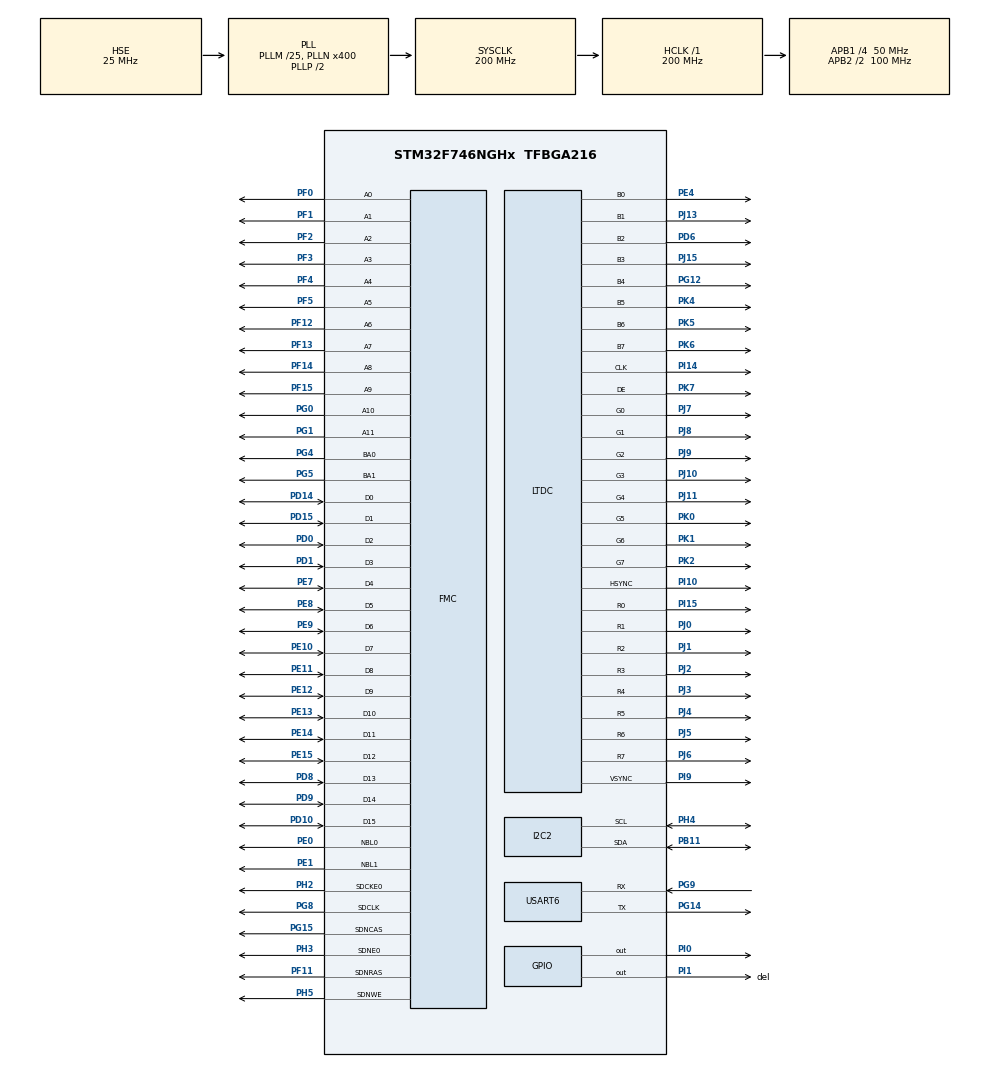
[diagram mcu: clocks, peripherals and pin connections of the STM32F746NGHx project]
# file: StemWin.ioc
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CORTEX_M7.AccessPermission-Cortex_Memory_Protection_Unit_Region0_Settings=MPU_REGION_FULL_ACCESS
CORTEX_M7.AccessPermission-Cortex_Memory_Protection_Unit_Region1_Settings=MPU_REGION_FULL_ACCESS
CORTEX_M7.AccessPermission-Cortex_Memory_Protection_Unit_Region2_Settings=MPU_REGION_FULL_ACCESS
CORTEX_M7.AccessPermission-Cortex_Memory_Protection_Unit_Region3_Settings=MPU_REGION_FULL_ACCESS
CORTEX_M7.BaseAddress-Cortex_Memory_Protection_Unit_Region0_Settings=0xC0000000
CORTEX_M7.BaseAddress-Cortex_Memory_Protection_Unit_Region1_Settings=0x2004C000
CORTEX_M7.BaseAddress-Cortex_Memory_Protection_Unit_Region2_Settings=0x2004C000
CORTEX_M7.BaseAddress-Cortex_Memory_Protection_Unit_Region3_Settings=0x20010000
CORTEX_M7.CPU_DCache=Enabled
CORTEX_M7.CPU_ICache=Enabled
CORTEX_M7.Enable-Cortex_Memory_Protection_Unit_Region0_Settings=MPU_REGION_ENABLE
CORTEX_M7.Enable-Cortex_Memory_Protection_Unit_Region1_Settings=MPU_REGION_ENABLE
CORTEX_M7.Enable-Cortex_Memory_Protection_Unit_Region2_Settings=MPU_REGION_ENABLE
CORTEX_M7.Enable-Cortex_Memory_Protection_Unit_Region3_Settings=MPU_REGION_ENABLE
CORTEX_M7.IsCacheable-Cortex_Memory_Protection_Unit_Region0_Settings=MPU_ACCESS_CACHEABLE
CORTEX_M7.MPU_Control=__NULL
CORTEX_M7.Size-Cortex_Memory_Protection_Unit_Region0_Settings=MPU_REGION_SIZE_8MB
CORTEX_M7.Size-Cortex_Memory_Protection_Unit_Region1_Settings=MPU_REGION_SIZE_16KB
CORTEX_M7.Size-Cortex_Memory_Protection_Unit_Region2_Settings=MPU_REGION_SIZE_512B
CORTEX_M7.Size-Cortex_Memory_Protection_Unit_Region3_Settings=MPU_REGION_SIZE_256KB
Dma.MEMTOMEM.0.Direction=DMA_MEMORY_TO_MEMORY
Dma.MEMTOMEM.0.FIFOMode=DMA_FIFOMODE_ENABLE
Dma.MEMTOMEM.0.FIFOThreshold=DMA_FIFO_THRESHOLD_FULL
Dma.MEMTOMEM.0.Instance=DMA2_Stream0
Dma.MEMTOMEM.0.MemBurst=DMA_MBURST_SINGLE
Dma.MEMTOMEM.0.MemDataAlignment=DMA_MDATAALIGN_BYTE
Dma.MEMTOMEM.0.MemInc=DMA_MINC_ENABLE
Dma.MEMTOMEM.0.Mode=DMA_NORMAL
Dma.MEMTOMEM.0.PeriphBurst=DMA_PBURST_SINGLE
Dma.MEMTOMEM.0.PeriphDataAlignment=DMA_PDATAALIGN_BYTE
Dma.MEMTOMEM.0.PeriphInc=DMA_PINC_ENABLE
Dma.MEMTOMEM.0.Priority=DMA_PRIORITY_LOW
Dma.Request0=MEMTOMEM
I2C2.Timing=0x00C0EAFF
LTDC.ActiveH=272
LTDC.ActiveW=480
LTDC.Alpha_L0=255
LTDC.BlendingFactor1_L0=LTDC_BLENDING_FACTOR1_PAxCA
LTDC.BlendingFactor2_L0=LTDC_BLENDING_FACTOR2_PAxCA
LTDC.FBStartAdress_L0=0xC0000000
LTDC.HBP=13
LTDC.HFP=32
LTDC.HSync=41
LTDC.ImageHeight_L0=272
LTDC.ImageWidth_L0=480
LTDC.Layers=0
LTDC.PixelFormat_L0=LTDC_PIXEL_FORMAT_RGB565
LTDC.VSync=10
LTDC.WindowX1_L0=480
LTDC.WindowY1_L0=272
Mcu.Family=STM32F7
Mcu.Name=STM32F746NGHx
Mcu.Package=TFBGA216
NVIC.DMA2D_IRQn=true\:5\:0\:true\:false\:true\:true\:true
NVIC.LTDC_IRQn=true\:5\:0\:true\:false\:true\:true\:true
NVIC.PriorityGroup=NVIC_PRIORITYGROUP_4
PA13.Mode=Trace_Asynchronous_SW
PA13.Signal=SYS_JTMS-SWDIO
PA14.Mode=Trace_Asynchronous_SW
PA14.Signal=SYS_JTCK-SWCLK
PB11.Mode=I2C
PB11.Signal=I2C2_SDA
PB3.Mode=Trace_Asynchronous_SW
PB3.Signal=SYS_JTDO-SWO
PC14/OSC32_IN.Mode=LSE-External-Oscillator
PC14/OSC32_IN.Signal=RCC_OSC32_IN
PC15/OSC32_OUT.Mode=LSE-External-Oscillator
PC15/OSC32_OUT.Signal=RCC_OSC32_OUT
PD0.Signal=FMC_D2_DA2
PD1.Signal=FMC_D3_DA3
PD10.Signal=FMC_D15_DA15
PD14.Signal=FMC_D0_DA0
PD15.Signal=FMC_D1_DA1
PD6.Mode=RGB888
PD6.Signal=LTDC_B2
PD8.Signal=FMC_D13_DA13
PD9.Signal=FMC_D14_DA14
PE0.Signal=FMC_NBL0
PE1.Signal=FMC_NBL1
PE10.Signal=FMC_D7_DA7
PE11.Signal=FMC_D8_DA8
PE12.Signal=FMC_D9_DA9
PE13.Signal=FMC_D10_DA10
PE14.Signal=FMC_D11_DA11
PE15.Signal=FMC_D12_DA12
PE4.Mode=RGB888
PE4.Signal=LTDC_B0
PE7.Signal=FMC_D4_DA4
PE8.Signal=FMC_D5_DA5
PE9.Signal=FMC_D6_DA6
PF0.Signal=FMC_A0
PF1.Signal=FMC_A1
PF11.Signal=FMC_SDNRAS
PF12.Signal=FMC_A6
PF13.Signal=FMC_A7
PF14.Signal=FMC_A8
PF15.Signal=FMC_A9
PF2.Signal=FMC_A2
PF3.Signal=FMC_A3
PF4.Signal=FMC_A4
PF5.Signal=FMC_A5
PG0.Signal=FMC_A10
PG1.Signal=FMC_A11
PG12.Mode=RGB888
PG12.Signal=LTDC_B4
PG14.Mode=Asynchronous
PG14.Signal=USART6_TX
PG15.Signal=FMC_SDNCAS
PG4.Signal=FMC_A14_BA0
PG5.Signal=FMC_A15_BA1
PG8.Signal=FMC_SDCLK
PG9.Mode=Asynchronous
PG9.Signal=USART6_RX
PH0/OSC_IN.Mode=HSE-External-Oscillator
PH0/OSC_IN.Signal=RCC_OSC_IN
PH1/OSC_OUT.Mode=HSE-External-Oscillator
PH1/OSC_OUT.Signal=RCC_OSC_OUT
PH2.Mode=SdramChipSelect1_1
PH2.Signal=FMC_SDCKE0
PH3.Mode=SdramChipSelect1_1
PH3.Signal=FMC_SDNE0
PH4.Mode=I2C
PH4.Signal=I2C2_SCL
PH5.Signal=FMC_SDNWE
PI0.Signal=GPIO_Output
PI1.GPIO_Label=del
PI1.Signal=GPIO_Output
PI10.Mode=RGB888
PI10.Signal=LTDC_HSYNC
PI14.Mode=RGB888
PI14.Signal=LTDC_CLK
PI15.Mode=RGB888
PI15.Signal=LTDC_R0
PI9.Mode=RGB888
PI9.Signal=LTDC_VSYNC
PJ0.Mode=RGB888
PJ0.Signal=LTDC_R1
PJ1.Mode=RGB888
PJ1.Signal=LTDC_R2
PJ10.Mode=RGB888
PJ10.Signal=LTDC_G3
PJ11.Mode=RGB888
PJ11.Signal=LTDC_G4
PJ13.Mode=RGB888
PJ13.Signal=LTDC_B1
PJ15.Mode=RGB888
PJ15.Signal=LTDC_B3
PJ2.Mode=RGB888
PJ2.Signal=LTDC_R3
PJ3.Mode=RGB888
PJ3.Signal=LTDC_R4
PJ4.Mode=RGB888
PJ4.Signal=LTDC_R5
PJ5.Mode=RGB888
PJ5.Signal=LTDC_R6
PJ6.Mode=RGB888
PJ6.Signal=LTDC_R7
PJ7.Mode=RGB888
PJ7.Signal=LTDC_G0
PJ8.Mode=RGB888
PJ8.Signal=LTDC_G1
PJ9.Mode=RGB888
PJ9.Signal=LTDC_G2
PK0.Mode=RGB888
PK0.Signal=LTDC_G5
PK1.Mode=RGB888
PK1.Signal=LTDC_G6
PK2.Mode=RGB888
PK2.Signal=LTDC_G7
PK4.Mode=RGB888
PK4.Signal=LTDC_B5
PK5.Mode=RGB888
PK5.Signal=LTDC_B6
PK6.Mode=RGB888
PK6.Signal=LTDC_B7
PK7.Mode=RGB888
PK7.Signal=LTDC_DE
ProjectManager.HeapSize=0x200
ProjectManager.StackSize=0x460
ProjectManager.TargetToolchain=Makefile
RCC.AHBFreq_Value=200000000
RCC.APB1CLKDivider=RCC_HCLK_DIV4
RCC.APB1Freq_Value=50000000
RCC.APB1TimFreq_Value=100000000
RCC.APB2CLKDivider=RCC_HCLK_DIV2
RCC.APB2Freq_Value=100000000
RCC.APB2TimFreq_Value=200000000
RCC.CortexFreq_Value=200000000
RCC.HCLKFreq_Value=200000000
RCC.HSE_VALUE=25000000
RCC.HSI_VALUE=16000000
RCC.PLL48CLockSelection=RCC_CLK48SOURCE_PLLSAIP
RCC.PLLI2SN=100
RCC.PLLM=25
RCC.PLLN=400
RCC.PLLQ=9
RCC.PLLSAIN=384
RCC.PLLSAIP=RCC_PLLSAIP_DIV8
RCC.PLLSAIR=5
RCC.PLLSAIRDiv=RCC_PLLSAIDIVR_8
RCC.PLLSourceVirtual=RCC_PLLSOURCE_HSE
RCC.SDMMCClockSelection=RCC_SDMMC1CLKSOURCE_CLK48
RCC.SYSCLKFreq_VALUE=200000000
RCC.SYSCLKSource=RCC_SYSCLKSOURCE_PLLCLK
RCC.USBFreq_Value=48000000
RCC.VCOOutputFreq_Value=400000000
SH.FMC_A0.0=FMC_A0,12b-sda1
SH.FMC_A1.0=FMC_A1,12b-sda1
SH.FMC_A10.0=FMC_A10,12b-sda1
SH.FMC_A11.0=FMC_A11,12b-sda1
SH.FMC_A14_BA0.0=FMC_BA0,FourSdramBanks1
SH.FMC_A15_BA1.0=FMC_BA1,FourSdramBanks1
SH.FMC_A2.0=FMC_A2,12b-sda1
SH.FMC_A3.0=FMC_A3,12b-sda1
SH.FMC_A4.0=FMC_A4,12b-sda1
SH.FMC_A5.0=FMC_A5,12b-sda1
SH.FMC_A6.0=FMC_A6,12b-sda1
SH.FMC_A7.0=FMC_A7,12b-sda1
SH.FMC_A8.0=FMC_A8,12b-sda1
SH.FMC_A9.0=FMC_A9,12b-sda1
SH.FMC_D0_DA0.0=FMC_D0,sd-16b-d1
SH.FMC_D10_DA10.0=FMC_D10,sd-16b-d1
SH.FMC_D11_DA11.0=FMC_D11,sd-16b-d1
SH.FMC_D12_DA12.0=FMC_D12,sd-16b-d1
SH.FMC_D13_DA13.0=FMC_D13,sd-16b-d1
SH.FMC_D14_DA14.0=FMC_D14,sd-16b-d1
SH.FMC_D15_DA15.0=FMC_D15,sd-16b-d1
SH.FMC_D1_DA1.0=FMC_D1,sd-16b-d1
SH.FMC_D2_DA2.0=FMC_D2,sd-16b-d1
SH.FMC_D3_DA3.0=FMC_D3,sd-16b-d1
SH.FMC_D4_DA4.0=FMC_D4,sd-16b-d1
SH.FMC_D5_DA5.0=FMC_D5,sd-16b-d1
SH.FMC_D6_DA6.0=FMC_D6,sd-16b-d1
SH.FMC_D7_DA7.0=FMC_D7,sd-16b-d1
SH.FMC_D8_DA8.0=FMC_D8,sd-16b-d1
SH.FMC_D9_DA9.0=FMC_D9,sd-16b-d1
SH.FMC_NBL0.0=FMC_NBL0,Sd2ByteEnable1
SH.FMC_NBL1.0=FMC_NBL1,Sd2ByteEnable1
SH.FMC_SDCLK.0=FMC_SDCLK,12b-sda1
SH.FMC_SDNCAS.0=FMC_SDNCAS,12b-sda1
SH.FMC_SDNRAS.0=FMC_SDNRAS,12b-sda1
SH.FMC_SDNWE.0=FMC_SDNWE,12b-sda1
USART6.VirtualMode-Asynchronous=VM_ASYNC
VP_CRC_VS_CRC.Mode=CRC_Activate
VP_DMA2D_VS_DMA2D.Mode=DMA2D_Activate
board=STM32F746G-DISCO

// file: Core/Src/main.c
/* USER CODE BEGIN Header */
/**
  ******************************************************************************
  * @file           : main.c
  * @brief          : Main program body
  ******************************************************************************
  * @attention
  *
  * <h2><center>&copy; Copyright (c) 2020 STMicroelectronics.
  * All rights reserved.</center></h2>
  *
  * This software component is licensed by ST under Ultimate Liberty license
  * SLA0044, the "License"; You may not use this file except in compliance with
  * the License. You may obtain a copy of the License at:
  *                             www.st.com/SLA0044
  *
  ******************************************************************************
  */
/* USER CODE END Header */
#include "main.h"

/* USER CODE BEGIN Includes */
#include <string.h>
#include <stdio.h>
#include "FramewinDLG.h"
/* USER CODE END Includes */

/* USER CODE BEGIN PD */
/* USER CODE BEGIN PFP */
 struct __FILE
{
  int handle;
  /* Whatever you require here. If the only file you are using is */
  /* standard output using printf() for debugging, no file handling */
  /* is required. */
};
int _write(int32_t file, uint8_t *ptr, int32_t len)
{
  /* Implement your write code here, this is used by puts and printf for example */
  int i=0;
  for(i=0 ; i<len ; i++)
    ITM_SendChar((*ptr++));
  return len;
}

/* USER CODE END PD */

CRC_HandleTypeDef hcrc;

DMA2D_HandleTypeDef hdma2d;

I2C_HandleTypeDef hi2c2;

LTDC_HandleTypeDef hltdc;

UART_HandleTypeDef huart6;

DMA_HandleTypeDef hdma_memtomem_dma2_stream0;
SDRAM_HandleTypeDef hsdram1;

void SystemClock_Config(void);
static void MX_GPIO_Init(void);
static void MX_DMA_Init(void);
static void MX_CRC_Init(void);
static void MX_USART6_UART_Init(void);
static void MX_I2C2_Init(void);
static void MX_DMA2D_Init(void);
static void MX_FMC_Init(void);
static void MX_LTDC_Init(void);
/* USER CODE BEGIN PFP */
extern volatile GUI_TIMER_TIME OS_TimeMS;
void HAL_SYSTICK_Callback(void)
{
		OS_TimeMS++;
}

/* USER CODE END PFP */

int main(void)
{

  /* Enable I-Cache---------------------------------------------------------*/
  SCB_EnableICache();

  /* Enable D-Cache---------------------------------------------------------*/
  SCB_EnableDCache();

  /* MCU Configuration--------------------------------------------------------*/

  /* Reset of all peripherals, Initializes the Flash interface and the Systick. */
  HAL_Init();

  /* USER CODE BEGIN Init */
  __HAL_RCC_CRC_CLK_ENABLE();
  /* USER CODE END Init */

  /* Configure the system clock */
  SystemClock_Config();

  /* USER CODE BEGIN SysInit */
BSP_LED_Init(LED1);
  /* USER CODE END SysInit */

  /* Initialize all configured peripherals */
  MX_GPIO_Init();
  MX_DMA_Init();
  MX_CRC_Init();
  MX_USART6_UART_Init();
  MX_I2C2_Init();
  MX_DMA2D_Init();
  MX_FMC_Init();
  MX_LTDC_Init();
  /* USER CODE BEGIN 2 */
  printf("begin Loop \r\n");
   BSP_SDRAM_Init(); /* Initializes the SDRAM device */
  __HAL_RCC_CRC_CLK_ENABLE(); /* Enable the CRC Module */
   printf("begin Loop 1 \r\n");
  GUI_Init();
  printf("begin Loop 2 \r\n");
  GUI_DispStringAt("Starting...", 0, 0);
  CreateFramewin();

  GUI_Exec();
  /* USER CODE END 2 */

  /* Infinite loop */
  /* USER CODE BEGIN WHILE */
printf("begin Loop 3 \r\n");

  while (1)
  {
    GUI_Exec();
    printf("Loop \r\n");
    HAL_GPIO_TogglePin(GPIOI, GPIO_PIN_1);
    GUI_Delay(500);
    /* USER CODE END WHILE */

  }
}

void SystemClock_Config(void)
{
  RCC_OscInitTypeDef RCC_OscInitStruct = {0};
  RCC_ClkInitTypeDef RCC_ClkInitStruct = {0};
  RCC_PeriphCLKInitTypeDef PeriphClkInitStruct = {0};

  /** Configure LSE Drive Capability
  */
  HAL_PWR_EnableBkUpAccess();
  /** Configure the main internal regulator output voltage
  */
  __HAL_RCC_PWR_CLK_ENABLE();
  __HAL_PWR_VOLTAGESCALING_CONFIG(PWR_REGULATOR_VOLTAGE_SCALE1);
  /** Initializes the RCC Oscillators according to the specified parameters
  * in the RCC_OscInitTypeDef structure.
  */
  RCC_OscInitStruct.OscillatorType = RCC_OSCILLATORTYPE_HSE;
  RCC_OscInitStruct.HSEState = RCC_HSE_ON;
  RCC_OscInitStruct.PLL.PLLState = RCC_PLL_ON;
  RCC_OscInitStruct.PLL.PLLSource = RCC_PLLSOURCE_HSE;
  RCC_OscInitStruct.PLL.PLLM = 25;
  RCC_OscInitStruct.PLL.PLLN = 400;
  RCC_OscInitStruct.PLL.PLLP = RCC_PLLP_DIV2;
  RCC_OscInitStruct.PLL.PLLQ = 9;
  if (HAL_RCC_OscConfig(&RCC_OscInitStruct) != HAL_OK)
  {
    Error_Handler();
  }
  /** Activate the Over-Drive mode
  */
  if (HAL_PWREx_EnableOverDrive() != HAL_OK)
  {
    Error_Handler();
  }
  /** Initializes the CPU, AHB and APB buses clocks
  */
  RCC_ClkInitStruct.ClockType = RCC_CLOCKTYPE_HCLK|RCC_CLOCKTYPE_SYSCLK
                              |RCC_CLOCKTYPE_PCLK1|RCC_CLOCKTYPE_PCLK2;
  RCC_ClkInitStruct.SYSCLKSource = RCC_SYSCLKSOURCE_PLLCLK;
  RCC_ClkInitStruct.AHBCLKDivider = RCC_SYSCLK_DIV1;
  RCC_ClkInitStruct.APB1CLKDivider = RCC_HCLK_DIV4;
  RCC_ClkInitStruct.APB2CLKDivider = RCC_HCLK_DIV2;

  if (HAL_RCC_ClockConfig(&RCC_ClkInitStruct, FLASH_LATENCY_6) != HAL_OK)
  {
    Error_Handler();
  }
  PeriphClkInitStruct.PeriphClockSelection = RCC_PERIPHCLK_LTDC|RCC_PERIPHCLK_USART6
                              |RCC_PERIPHCLK_I2C2;
  PeriphClkInitStruct.PLLSAI.PLLSAIN = 384;
  PeriphClkInitStruct.PLLSAI.PLLSAIR = 5;
  PeriphClkInitStruct.PLLSAI.PLLSAIQ = 2;
  PeriphClkInitStruct.PLLSAI.PLLSAIP = RCC_PLLSAIP_DIV8;
  PeriphClkInitStruct.PLLSAIDivQ = 1;
  PeriphClkInitStruct.PLLSAIDivR = RCC_PLLSAIDIVR_8;
  PeriphClkInitStruct.Usart6ClockSelection = RCC_USART6CLKSOURCE_PCLK2;
  PeriphClkInitStruct.I2c2ClockSelection = RCC_I2C2CLKSOURCE_PCLK1;
  if (HAL_RCCEx_PeriphCLKConfig(&PeriphClkInitStruct) != HAL_OK)
  {
    Error_Handler();
  }
}

static void MX_CRC_Init(void)
{

  hcrc.Instance = CRC;
  hcrc.Init.DefaultPolynomialUse = DEFAULT_POLYNOMIAL_ENABLE;
  hcrc.Init.DefaultInitValueUse = DEFAULT_INIT_VALUE_ENABLE;
  hcrc.Init.InputDataInversionMode = CRC_INPUTDATA_INVERSION_NONE;
  hcrc.Init.OutputDataInversionMode = CRC_OUTPUTDATA_INVERSION_DISABLE;
  hcrc.InputDataFormat = CRC_INPUTDATA_FORMAT_BYTES;
  if (HAL_CRC_Init(&hcrc) != HAL_OK)
  {
    Error_Handler();
  }

}

static void MX_DMA2D_Init(void)
{

  hdma2d.Instance = DMA2D;
  hdma2d.Init.Mode = DMA2D_M2M;
  hdma2d.Init.ColorMode = DMA2D_OUTPUT_ARGB8888;
  hdma2d.Init.OutputOffset = 0;
  hdma2d.LayerCfg[1].InputOffset = 0;
  hdma2d.LayerCfg[1].InputColorMode = DMA2D_INPUT_ARGB8888;
  hdma2d.LayerCfg[1].AlphaMode = DMA2D_NO_MODIF_ALPHA;
  hdma2d.LayerCfg[1].InputAlpha = 0;
  if (HAL_DMA2D_Init(&hdma2d) != HAL_OK)
  {
    Error_Handler();
  }
  if (HAL_DMA2D_ConfigLayer(&hdma2d, 1) != HAL_OK)
  {
    Error_Handler();
  }

}

static void MX_I2C2_Init(void)
{

  hi2c2.Instance = I2C2;
  hi2c2.Init.Timing = 0x00C0EAFF;
  hi2c2.Init.OwnAddress1 = 0;
  hi2c2.Init.AddressingMode = I2C_ADDRESSINGMODE_7BIT;
  hi2c2.Init.DualAddressMode = I2C_DUALADDRESS_DISABLE;
  hi2c2.Init.OwnAddress2 = 0;
  hi2c2.Init.OwnAddress2Masks = I2C_OA2_NOMASK;
  hi2c2.Init.GeneralCallMode = I2C_GENERALCALL_DISABLE;
  hi2c2.Init.NoStretchMode = I2C_NOSTRETCH_DISABLE;
  if (HAL_I2C_Init(&hi2c2) != HAL_OK)
  {
    Error_Handler();
  }
  /** Configure Analogue filter
  */
  if (HAL_I2CEx_ConfigAnalogFilter(&hi2c2, I2C_ANALOGFILTER_ENABLE) != HAL_OK)
  {
    Error_Handler();
  }
  /** Configure Digital filter
  */
  if (HAL_I2CEx_ConfigDigitalFilter(&hi2c2, 0) != HAL_OK)
  {
    Error_Handler();
  }

}

static void MX_LTDC_Init(void)
{

  LTDC_LayerCfgTypeDef pLayerCfg = {0};
  LTDC_LayerCfgTypeDef pLayerCfg1 = {0};

  hltdc.Instance = LTDC;
  hltdc.Init.HSPolarity = LTDC_HSPOLARITY_AL;
  hltdc.Init.VSPolarity = LTDC_VSPOLARITY_AL;
  hltdc.Init.DEPolarity = LTDC_DEPOLARITY_AL;
  hltdc.Init.PCPolarity = LTDC_PCPOLARITY_IPC;
  hltdc.Init.HorizontalSync = 40;
  hltdc.Init.VerticalSync = 9;
  hltdc.Init.AccumulatedHBP = 53;
  hltdc.Init.AccumulatedVBP = 11;
  hltdc.Init.AccumulatedActiveW = 533;
  hltdc.Init.AccumulatedActiveH = 283;
  hltdc.Init.TotalWidth = 565;
  hltdc.Init.TotalHeigh = 285;
  hltdc.Init.Backcolor.Blue = 0;
  hltdc.Init.Backcolor.Green = 0;
  hltdc.Init.Backcolor.Red = 0;
  if (HAL_LTDC_Init(&hltdc) != HAL_OK)
  {
    Error_Handler();
  }
  pLayerCfg.WindowX0 = 0;
  pLayerCfg.WindowX1 = 480;
  pLayerCfg.WindowY0 = 0;
  pLayerCfg.WindowY1 = 272;
  pLayerCfg.PixelFormat = LTDC_PIXEL_FORMAT_RGB565;
  pLayerCfg.Alpha = 255;
  pLayerCfg.Alpha0 = 0;
  pLayerCfg.BlendingFactor1 = LTDC_BLENDING_FACTOR1_PAxCA;
  pLayerCfg.BlendingFactor2 = LTDC_BLENDING_FACTOR2_PAxCA;
  pLayerCfg.FBStartAdress = 0xC0000000;
  pLayerCfg.ImageWidth = 480;
  pLayerCfg.ImageHeight = 272;
  pLayerCfg.Backcolor.Blue = 0;
  pLayerCfg.Backcolor.Green = 0;
  pLayerCfg.Backcolor.Red = 0;
  if (HAL_LTDC_ConfigLayer(&hltdc, &pLayerCfg, 0) != HAL_OK)
  {
    Error_Handler();
  }
  pLayerCfg1.WindowX0 = 0;
  pLayerCfg1.WindowX1 = 0;
  pLayerCfg1.WindowY0 = 0;
  pLayerCfg1.WindowY1 = 0;
  pLayerCfg1.Alpha = 0;
  pLayerCfg1.Alpha0 = 0;
  pLayerCfg1.BlendingFactor1 = LTDC_BLENDING_FACTOR1_CA;
  pLayerCfg1.BlendingFactor2 = LTDC_BLENDING_FACTOR2_CA;
  pLayerCfg1.FBStartAdress = 0;
  pLayerCfg1.ImageWidth = 0;
  pLayerCfg1.ImageHeight = 0;
  pLayerCfg1.Backcolor.Blue = 0;
  pLayerCfg1.Backcolor.Green = 0;
  pLayerCfg1.Backcolor.Red = 0;
  if (HAL_LTDC_ConfigLayer(&hltdc, &pLayerCfg1, 1) != HAL_OK)
  {
    Error_Handler();
  }

}

static void MX_USART6_UART_Init(void)
{

  huart6.Instance = USART6;
  huart6.Init.BaudRate = 115200;
  huart6.Init.WordLength = UART_WORDLENGTH_8B;
  huart6.Init.StopBits = UART_STOPBITS_1;
  huart6.Init.Parity = UART_PARITY_NONE;
  huart6.Init.Mode = UART_MODE_TX_RX;
  huart6.Init.HwFlowCtl = UART_HWCONTROL_NONE;
  huart6.Init.OverSampling = UART_OVERSAMPLING_16;
  huart6.Init.OneBitSampling = UART_ONE_BIT_SAMPLE_DISABLE;
  huart6.AdvancedInit.AdvFeatureInit = UART_ADVFEATURE_NO_INIT;
  if (HAL_UART_Init(&huart6) != HAL_OK)
  {
    Error_Handler();
  }

}

static void MX_DMA_Init(void)
{

  /* DMA controller clock enable */
  __HAL_RCC_DMA2_CLK_ENABLE();

  /* Configure DMA request hdma_memtomem_dma2_stream0 on DMA2_Stream0 */
  hdma_memtomem_dma2_stream0.Instance = DMA2_Stream0;
  hdma_memtomem_dma2_stream0.Init.Channel = DMA_CHANNEL_0;
  hdma_memtomem_dma2_stream0.Init.Direction = DMA_MEMORY_TO_MEMORY;
  hdma_memtomem_dma2_stream0.Init.PeriphInc = DMA_PINC_ENABLE;
  hdma_memtomem_dma2_stream0.Init.MemInc = DMA_MINC_ENABLE;
  hdma_memtomem_dma2_stream0.Init.PeriphDataAlignment = DMA_PDATAALIGN_BYTE;
  hdma_memtomem_dma2_stream0.Init.MemDataAlignment = DMA_MDATAALIGN_BYTE;
  hdma_memtomem_dma2_stream0.Init.Mode = DMA_NORMAL;
  hdma_memtomem_dma2_stream0.Init.Priority = DMA_PRIORITY_LOW;
  hdma_memtomem_dma2_stream0.Init.FIFOMode = DMA_FIFOMODE_ENABLE;
  hdma_memtomem_dma2_stream0.Init.FIFOThreshold = DMA_FIFO_THRESHOLD_FULL;
  hdma_memtomem_dma2_stream0.Init.MemBurst = DMA_MBURST_SINGLE;
  hdma_memtomem_dma2_stream0.Init.PeriphBurst = DMA_PBURST_SINGLE;
  if (HAL_DMA_Init(&hdma_memtomem_dma2_stream0) != HAL_OK)
  {
    Error_Handler( );
  }

}

/* FMC initialization function */
static void MX_FMC_Init(void)
{

  FMC_SDRAM_TimingTypeDef SdramTiming = {0};

  /** Perform the SDRAM1 memory initialization sequence
  */
  hsdram1.Instance = FMC_SDRAM_DEVICE;
  /* hsdram1.Init */
  hsdram1.Init.SDBank = FMC_SDRAM_BANK1;
  hsdram1.Init.ColumnBitsNumber = FMC_SDRAM_COLUMN_BITS_NUM_8;
  hsdram1.Init.RowBitsNumber = FMC_SDRAM_ROW_BITS_NUM_12;
  hsdram1.Init.MemoryDataWidth = FMC_SDRAM_MEM_BUS_WIDTH_16;
  hsdram1.Init.InternalBankNumber = FMC_SDRAM_INTERN_BANKS_NUM_4;
  hsdram1.Init.CASLatency = FMC_SDRAM_CAS_LATENCY_1;
  hsdram1.Init.WriteProtection = FMC_SDRAM_WRITE_PROTECTION_DISABLE;
  hsdram1.Init.SDClockPeriod = FMC_SDRAM_CLOCK_DISABLE;
  hsdram1.Init.ReadBurst = FMC_SDRAM_RBURST_DISABLE;
  hsdram1.Init.ReadPipeDelay = FMC_SDRAM_RPIPE_DELAY_0;
  /* SdramTiming */
  SdramTiming.LoadToActiveDelay = 16;
  SdramTiming.ExitSelfRefreshDelay = 16;
  SdramTiming.SelfRefreshTime = 16;
  SdramTiming.RowCycleDelay = 16;
  SdramTiming.WriteRecoveryTime = 16;
  SdramTiming.RPDelay = 16;
  SdramTiming.RCDDelay = 16;

  if (HAL_SDRAM_Init(&hsdram1, &SdramTiming) != HAL_OK)
  {
    Error_Handler( );
  }

}

static void MX_GPIO_Init(void)
{
  GPIO_InitTypeDef GPIO_InitStruct = {0};

  /* GPIO Ports Clock Enable */
  __HAL_RCC_GPIOE_CLK_ENABLE();
  __HAL_RCC_GPIOG_CLK_ENABLE();
  __HAL_RCC_GPIOB_CLK_ENABLE();
  __HAL_RCC_GPIOA_CLK_ENABLE();
  __HAL_RCC_GPIOJ_CLK_ENABLE();
  __HAL_RCC_GPIOD_CLK_ENABLE();
  __HAL_RCC_GPIOK_CLK_ENABLE();
  __HAL_RCC_GPIOF_CLK_ENABLE();
  __HAL_RCC_GPIOI_CLK_ENABLE();
  __HAL_RCC_GPIOC_CLK_ENABLE();
  __HAL_RCC_GPIOH_CLK_ENABLE();

  /*Configure GPIO pin Output Level */
  HAL_GPIO_WritePin(GPIOI, del_Pin|GPIO_PIN_0, GPIO_PIN_RESET);

  /*Configure GPIO pins : del_Pin PI0 */
  GPIO_InitStruct.Pin = del_Pin|GPIO_PIN_0;
  GPIO_InitStruct.Mode = GPIO_MODE_OUTPUT_PP;
  GPIO_InitStruct.Pull = GPIO_NOPULL;
  GPIO_InitStruct.Speed = GPIO_SPEED_FREQ_LOW;
  HAL_GPIO_Init(GPIOI, &GPIO_InitStruct);

}

/* USER CODE BEGIN 4 */
static void MPU_Config(void)
{
  MPU_Region_InitTypeDef MPU_InitStruct;

  /* Disable the MPU */
  HAL_MPU_Disable();

  /* Configure the MPU attributes for SDRAM as WT */
  MPU_InitStruct.Enable = MPU_REGION_ENABLE;
  MPU_InitStruct.BaseAddress = SDRAM_DEVICE_ADDR;
  MPU_InitStruct.Size = MPU_REGION_SIZE_8MB;
  MPU_InitStruct.AccessPermission = MPU_REGION_FULL_ACCESS;
  MPU_InitStruct.IsBufferable = MPU_ACCESS_NOT_BUFFERABLE;
  MPU_InitStruct.IsCacheable = MPU_ACCESS_CACHEABLE;
  MPU_InitStruct.IsShareable = MPU_ACCESS_NOT_SHAREABLE;
  MPU_InitStruct.Number = MPU_REGION_NUMBER3;
  MPU_InitStruct.TypeExtField = MPU_TEX_LEVEL0;
  MPU_InitStruct.SubRegionDisable = 0x00;
  MPU_InitStruct.DisableExec = MPU_INSTRUCTION_ACCESS_ENABLE;

  HAL_MPU_ConfigRegion(&MPU_InitStruct);

  /* Configure the MPU as Normal Non Cacheable for Ethernet Buffers in the SRAM2 */
  MPU_InitStruct.Enable = MPU_REGION_ENABLE;
  MPU_InitStruct.BaseAddress = 0x2004C000;
  MPU_InitStruct.Size = MPU_REGION_SIZE_16KB;
  MPU_InitStruct.AccessPermission = MPU_REGION_FULL_ACCESS;
  MPU_InitStruct.IsBufferable = MPU_ACCESS_NOT_BUFFERABLE;
  MPU_InitStruct.IsCacheable = MPU_ACCESS_NOT_CACHEABLE;
  MPU_InitStruct.IsShareable = MPU_ACCESS_SHAREABLE;
  MPU_InitStruct.Number = MPU_REGION_NUMBER0;
  MPU_InitStruct.TypeExtField = MPU_TEX_LEVEL1;
  MPU_InitStruct.SubRegionDisable = 0x00;
  MPU_InitStruct.DisableExec = MPU_INSTRUCTION_ACCESS_ENABLE;

  HAL_MPU_ConfigRegion(&MPU_InitStruct);

  /* Configure the MPU as Device for Ethernet Descriptors in the SRAM2 */
  MPU_InitStruct.Enable = MPU_REGION_ENABLE;
  MPU_InitStruct.BaseAddress = 0x2004C000;
  MPU_InitStruct.Size = MPU_REGION_SIZE_512B;
  MPU_InitStruct.AccessPermission = MPU_REGION_FULL_ACCESS;
  MPU_InitStruct.IsBufferable = MPU_ACCESS_BUFFERABLE;
  MPU_InitStruct.IsCacheable = MPU_ACCESS_NOT_CACHEABLE;
  MPU_InitStruct.IsShareable = MPU_ACCESS_SHAREABLE;
  MPU_InitStruct.Number = MPU_REGION_NUMBER1;
  MPU_InitStruct.TypeExtField = MPU_TEX_LEVEL0;
  MPU_InitStruct.SubRegionDisable = 0x00;
  MPU_InitStruct.DisableExec = MPU_INSTRUCTION_ACCESS_ENABLE;

  HAL_MPU_ConfigRegion(&MPU_InitStruct);

/*
@Note It is recommended to enable the cache and maintain its coherence, but depending on the use case
      It is also possible to configure the MPU as "Write through", to guarantee the write access coherence.
      In that case, the MPU must be configured as Cacheable/Bufferable/Not Shareable.
      Even though the user must manage the cache coherence for read accesses.
      Please refer to the AN4838 “Managing memory protection unit (MPU) in STM32 MCUs�?
      Please refer to the AN4839 “Level 1 cache on STM32F7 Series�?
*/
  //Cacheable/Bufferable/Not Shareable.

  MPU_InitStruct.Enable = MPU_REGION_ENABLE;
  MPU_InitStruct.BaseAddress = 0x20010000;
  MPU_InitStruct.Size = MPU_REGION_SIZE_256KB;
  MPU_InitStruct.AccessPermission = MPU_REGION_FULL_ACCESS;
  MPU_InitStruct.IsBufferable = MPU_ACCESS_NOT_BUFFERABLE;
  MPU_InitStruct.IsCacheable = MPU_ACCESS_CACHEABLE;
  MPU_InitStruct.IsShareable = MPU_ACCESS_SHAREABLE;
  MPU_InitStruct.Number = MPU_REGION_NUMBER2;
  MPU_InitStruct.TypeExtField = MPU_TEX_LEVEL0;
  MPU_InitStruct.SubRegionDisable = 0x00;
  MPU_InitStruct.DisableExec = MPU_INSTRUCTION_ACCESS_ENABLE;

  HAL_MPU_ConfigRegion(&MPU_InitStruct);

  /* Enable the MPU */
  HAL_MPU_Enable(MPU_PRIVILEGED_DEFAULT);
}
/* USER CODE END 4 */

void Error_Handler(void)
{
}

/************************ (C) COPYRIGHT STMicroelectronics *****END OF FILE****/
